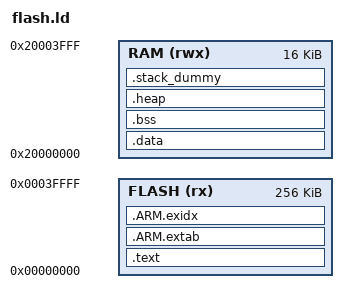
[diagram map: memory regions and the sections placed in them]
/****************************************************************************
**
** Copyright (C) 2020 Denis Shienkov <denis.shienkov@gmail.com>
** Contact: https://www.qt.io/licensing/
**
** This file is part of the examples of Qbs.
**
** $QT_BEGIN_LICENSE:BSD$
** Commercial License Usage
** Licensees holding valid commercial Qt licenses may use this file in
** accordance with the commercial license agreement provided with the
** Software or, alternatively, in accordance with the terms contained in
** a written agreement between you and The Qt Company. For licensing terms
** and conditions see https://www.qt.io/terms-conditions. For further
** information use the contact form at https://www.qt.io/contact-us.
**
** BSD License Usage
** Alternatively, you may use this file under the terms of the BSD license
** as follows:
**
** "Redistribution and use in source and binary forms, with or without
** modification, are permitted provided that the following conditions are
** met:
**   * Redistributions of source code must retain the above copyright
**     notice, this list of conditions and the following disclaimer.
**   * Redistributions in binary form must reproduce the above copyright
**     notice, this list of conditions and the following disclaimer in
**     the documentation and/or other materials provided with the
**     distribution.
**   * Neither the name of The Qt Company Ltd nor the names of its
**     contributors may be used to endorse or promote products derived
**     from this software without specific prior written permission.
**
**
** THIS SOFTWARE IS PROVIDED BY THE COPYRIGHT HOLDERS AND CONTRIBUTORS
** "AS IS" AND ANY EXPRESS OR IMPLIED WARRANTIES, INCLUDING, BUT NOT
** LIMITED TO, THE IMPLIED WARRANTIES OF MERCHANTABILITY AND FITNESS FOR
** A PARTICULAR PURPOSE ARE DISCLAIMED. IN NO EVENT SHALL THE COPYRIGHT
** OWNER OR CONTRIBUTORS BE LIABLE FOR ANY DIRECT, INDIRECT, INCIDENTAL,
** SPECIAL, EXEMPLARY, OR CONSEQUENTIAL DAMAGES (INCLUDING, BUT NOT
** LIMITED TO, PROCUREMENT OF SUBSTITUTE GOODS OR SERVICES; LOSS OF USE,
** DATA, OR PROFITS; OR BUSINESS INTERRUPTION) HOWEVER CAUSED AND ON ANY
** THEORY OF LIABILITY, WHETHER IN CONTRACT, STRICT LIABILITY, OR TORT
** (INCLUDING NEGLIGENCE OR OTHERWISE) ARISING IN ANY WAY OUT OF THE USE
** OF THIS SOFTWARE, EVEN IF ADVISED OF THE POSSIBILITY OF SUCH DAMAGE."
**
** $QT_END_LICENSE$
**
****************************************************************************/

ENTRY(reset_handler)

MEMORY
{
  FLASH (rx) : ORIGIN = 0x00000000, LENGTH = 0x40000
  RAM (rwx) : ORIGIN = 0x20000000, LENGTH = 0x4000
}

SECTIONS {
    .text : {
        KEEP(*(.isr_vector))
        *(.text*)
        KEEP(*(.init))
        KEEP(*(.fini))
        /* .ctors */
        *crtbegin.o(.ctors)
        *crtbegin?.o(.ctors)
        *(EXCLUDE_FILE(*crtend?.o *crtend.o) .ctors)
        *(SORT(.ctors.*))
        *(.ctors)
        /* .dtors */
         *crtbegin.o(.dtors)
         *crtbegin?.o(.dtors)
         *(EXCLUDE_FILE(*crtend?.o *crtend.o) .dtors)
         *(SORT(.dtors.*))
         *(.dtors)
        *(.rodata*)
        *(.eh_frame*)
        . = ALIGN(4);
    } > FLASH

    .ARM.extab : {
        *(.ARM.extab* .gnu.linkonce.armextab.*)
        . = ALIGN(4);
    } > FLASH

    _start_of_exidx_section = .;
    .ARM.exidx : {
        *(.ARM.exidx* .gnu.linkonce.armexidx.*)
        . = ALIGN(4);
    } > FLASH
    _end_of_exidx_section = .;

    _end_of_code_section = .;

    .data : AT (_end_of_code_section) {
        _start_of_data_section = .;
        *(vtable)
        *(.data*)
        . = ALIGN(4);
        /* preinit data */
        PROVIDE_HIDDEN(__preinit_array_start = .);
        *(.preinit_array)
        PROVIDE_HIDDEN(__preinit_array_end = .);
        . = ALIGN(4);
        /* init data */
        PROVIDE_HIDDEN(__init_array_start = .);
        *(SORT(.init_array.*))
        *(.init_array)
        PROVIDE_HIDDEN(__init_array_end = .);
        . = ALIGN(4);
        /* finit data */
        PROVIDE_HIDDEN(__fini_array_start = .);
        *(SORT(.fini_array.*))
        *(.fini_array)
        PROVIDE_HIDDEN(__fini_array_end = .);
        *(.jcr)
        . = ALIGN(4);
        /* All data end */
        _end_of_data_section = .;
    } > RAM

    .bss : {
        . = ALIGN(4);
        __bss_start__ = .;
        *(.bss*)
        *(COMMON)
        . = ALIGN(4);
        __bss_end__ = .;
    } > RAM

    .heap (COPY): {
        __end__ = .;
        end = __end__;
        *(.heap*)
        _heap_limit = .;
    } > RAM

    .stack_dummy (COPY): {
        *(.stack*)
    } > RAM

    /* Set stack top to end of RAM, and stack limit move down by size of stack_dummy section. */
    _end_of_stack = ORIGIN(RAM) + LENGTH(RAM);
    _stack_limit = _end_of_stack - SIZEOF(.stack_dummy);
    PROVIDE(__stack = _end_of_stack);

    /* Check if data + heap + stack exceeds RAM limit */
    ASSERT(_stack_limit >= _heap_limit, "region RAM overflowed with stack")
}
